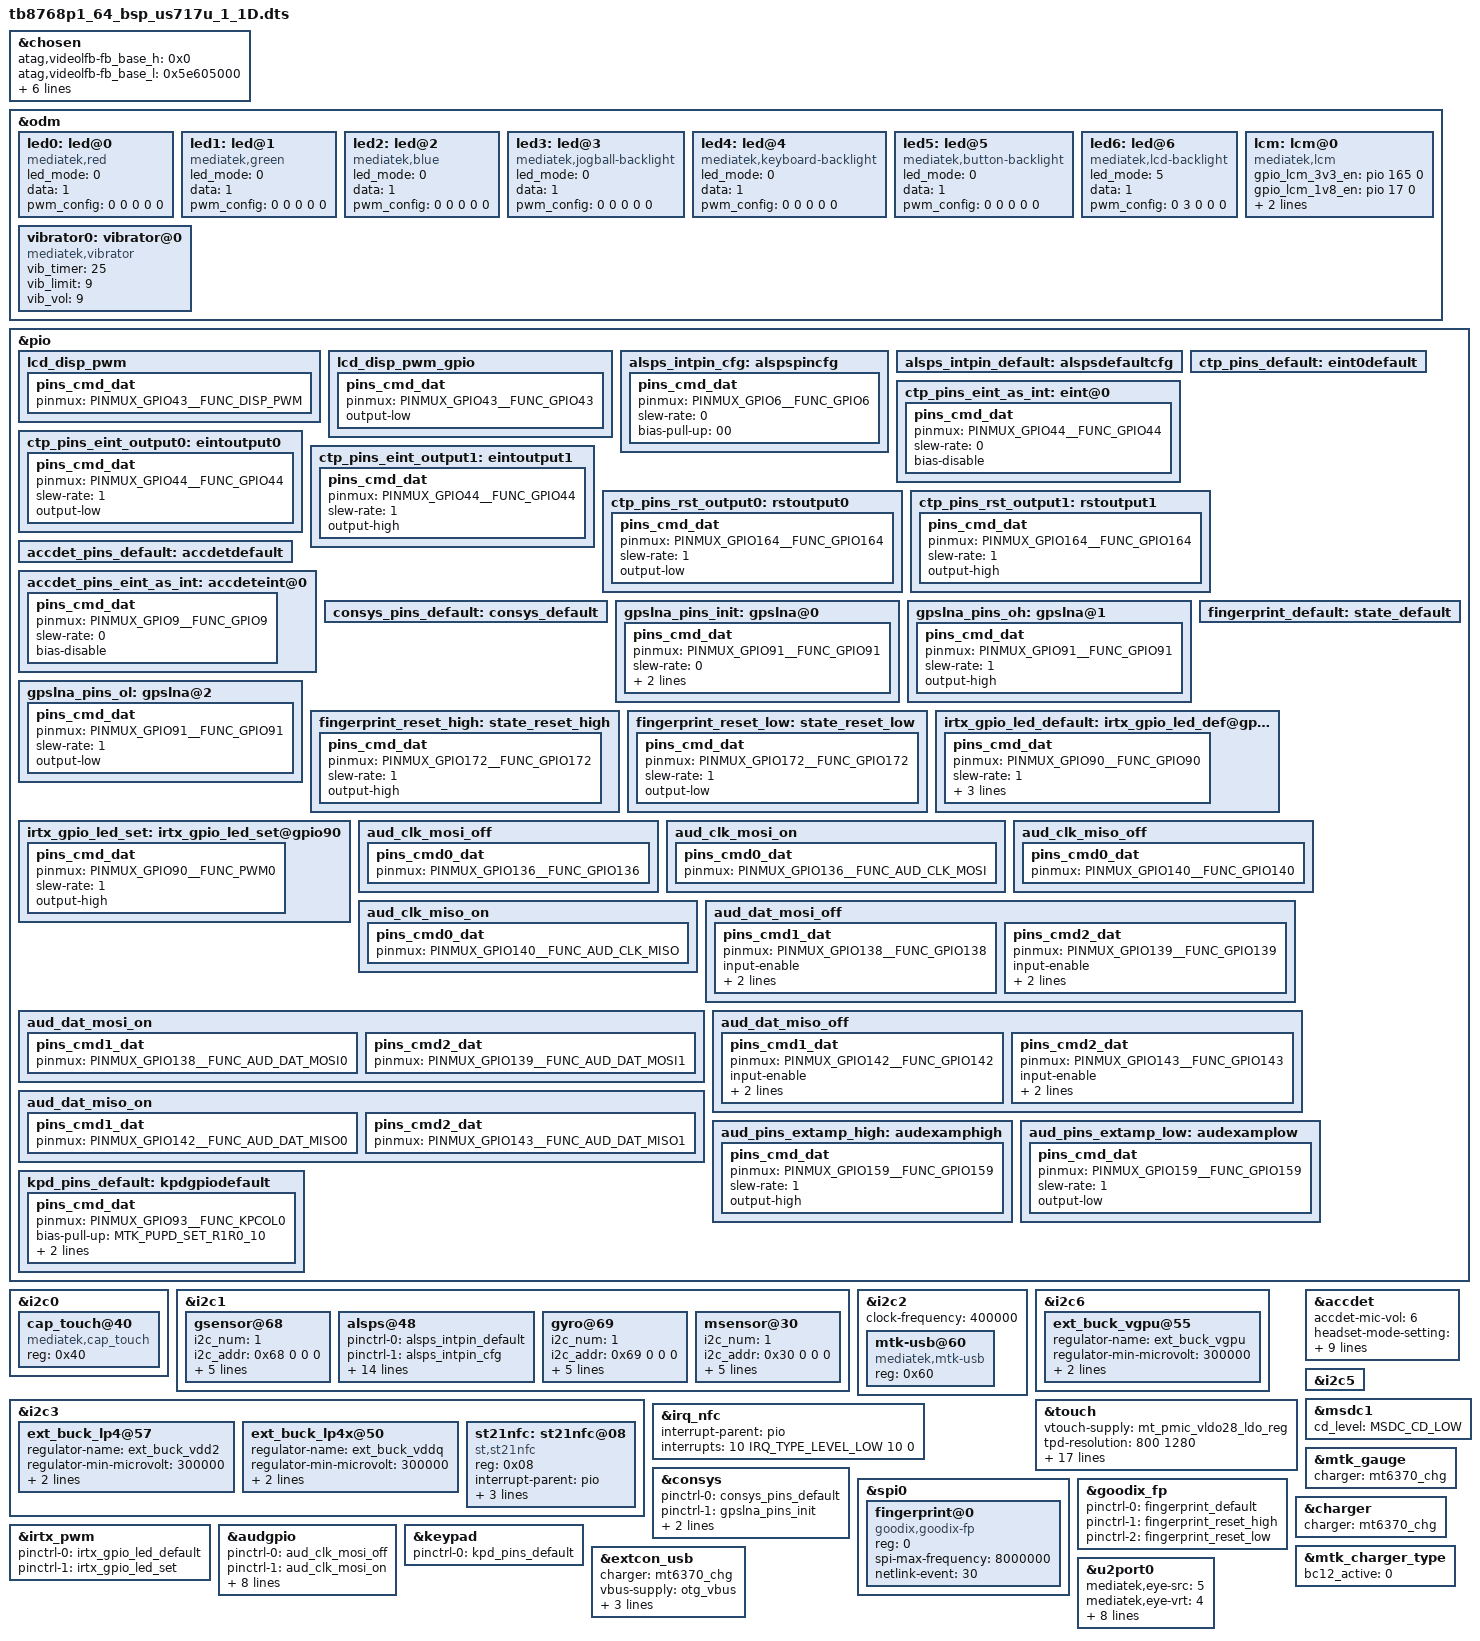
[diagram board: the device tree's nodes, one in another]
// SPDX-License-Identifier: GPL-2.0+
/*
 * Copyright (c) 2019 MediaTek Inc.
 *
 */

#include <dt-bindings/interrupt-controller/arm-gic.h>
#include <dt-bindings/interrupt-controller/irq.h>
#include <dt-bindings/pinctrl/mt6765-pinfunc.h>
#include <dt-bindings/clock/mt6765-clk.h>
#include <dt-bindings/mmc/mt6765-msdc.h>

/dts-v1/;
/plugin/;

/* chosen */
&chosen {

	/* fpga may has no lk, we need to specify display info here */
	/* fb buffer is reserved using this dts by memory node above */
	atag,videolfb-fb_base_h = <0x0>;
	atag,videolfb-fb_base_l = <0x5e605000>;
	atag,videolfb-islcmfound = <1>;
	/* because no lk, so lcm is not inited */
	atag,videolfb-islcm_inited = <0>;
	atag,videolfb-fps= <6000>;
	atag,videolfb-vramSize= <0x017bb000>;
	atag,videolfb-lcmname= "nt35695B_fhd_dsi_cmd_auo_rt5081_drv";
};

&odm {
	led0:led@0 {
		compatible = "mediatek,red";
		led_mode = <0>;
		data = <1>;
		pwm_config = <0 0 0 0 0>;
	};
	led1:led@1 {
		compatible = "mediatek,green";
		led_mode = <0>;
		data = <1>;
		pwm_config = <0 0 0 0 0>;
	};
	led2:led@2 {
		compatible = "mediatek,blue";
		led_mode = <0>;
		data = <1>;
		pwm_config = <0 0 0 0 0>;
	};
	led3:led@3 {
		compatible = "mediatek,jogball-backlight";
		led_mode = <0>;
		data = <1>;
		pwm_config = <0 0 0 0 0>;
	};
	led4:led@4 {
		compatible = "mediatek,keyboard-backlight";
		led_mode = <0>;
		data = <1>;
		pwm_config = <0 0 0 0 0>;
	};
	led5:led@5 {
		compatible = "mediatek,button-backlight";
		led_mode = <0>;
		data = <1>;
		pwm_config = <0 0 0 0 0>;
	};
	led6:led@6 {
		compatible = "mediatek,lcd-backlight";
		led_mode = <5>;
		data = <1>;
		pwm_config = <0 3 0 0 0>;
	};
	/*
	panel: panel@0 {
		compatible = "ft,ft8201";
		gpio_lcd_rst = <&pio 45 0>;
		gpio_lcd_led_en = <&pio 154 0>;
		gpio_lcd_pwr_enp = <&pio 167 0>;
		gpio_lcd_pwr_enn = <&pio 168 0>;
		pinctrl-names = "disp_pwm", "disp_pwm_gpio";
		pinctrl-0 = <&lcd_disp_pwm>;
		pinctrl-1 = <&lcd_disp_pwm_gpio>;
	};
	*/
	lcm: lcm@0{
		compatible = "mediatek,lcm";
		gpio_lcm_3v3_en = <&pio 165 0>; //3.3V
		gpio_lcm_1v8_en = <&pio 17 0>;
		gpio_lcm_rst = <&pio 45 0>;	 	//reset
		gpio_lcm_bias_en = <&pio 174 0>;//avdd avee
		status = "okay";
	};
	vibrator0:vibrator@0 {
		compatible = "mediatek,vibrator";
		vib_timer = <25>;
		vib_limit = <9>;
		vib_vol= <9>;
	};
};

&pio {
	lcd_disp_pwm: lcd_disp_pwm {
		pins_cmd_dat {
			pinmux = <PINMUX_GPIO43__FUNC_DISP_PWM>;
		};
	};

	lcd_disp_pwm_gpio: lcd_disp_pwm_gpio {
		pins_cmd_dat {
			pinmux = <PINMUX_GPIO43__FUNC_GPIO43>;
			output-low;
		};
	};
};

&i2c0 {
	cap_touch@40 {
		compatible = "mediatek,cap_touch" ;
		reg = < 0x40 > ;
		status = "okay" ;
	};
};
&i2c1 {
	gsensor@68{
		i2c_num = <1>;
		i2c_addr = <0x68 0 0 0>;
		direction = <7>;
		power_id = <0xffff>;
		power_vol = <0>;
		firlen = <16>;
		is_batch_supported = <0>;
	};
	
	alsps@48 {
		pinctrl-names = "pin_default", "pin_cfg";
		pinctrl-0 = <&alsps_intpin_default>;
		pinctrl-1 = <&alsps_intpin_cfg>;
		status = "okay";
		/* customization */
		i2c_num = <1>;
		i2c_addr = <0x48 0x0 0x0 0x00>;
		polling_mode_ps = <0>;
		polling_mode_als = <1>;
		power_id = <0xffff>;
		power_vol = <0>;
		als_level =
			<0 1 1 7 15 15 100 1000 2000 3000
			6000 10000 14000 18000 20000>;
		als_value =
			<40 40 90 90 160 160 225 320 640 1280
			1280 2600 2600 2600 10240 10240>;
		ps_threshold_high = <900>;
		ps_threshold_low = <600>;
		is_batch_supported_ps = <0>;
		is_batch_supported_als = <0>;
	};
	
	gyro@69 {
		i2c_num = <1>;
		i2c_addr = <0x69 0 0 0>;
		direction = <5>;
 		power_id = <0xffff>;
 		power_vol = <0>;
 		firlen = <16>;
 		is_batch_supported = <0>;
 	};

	msensor@30 {
		i2c_num = <1>;
		i2c_addr = <0x30 0 0 0>;
		direction = <6>;
		power_id = <0xffff>;
		power_vol = <0>;
		firlen = <16>;
		is_batch_supported = <0>;
	};
	
};
&i2c2 {
	#address-cells = <1>;
	#size-cells = <0>;
	clock-frequency = <400000>;

	mtk-usb@60 {
		compatible = "mediatek,mtk-usb";
		reg = <0x60>;
		status = "okay";
	};
};

&i2c3 {
	ext_buck_lp4@57 {
		regulator-name ="ext_buck_vdd2";
		regulator-min-microvolt = <300000>;
		regulator-max-microvolt = <1300000>;
		vsel_pin = <0>;
	};

	ext_buck_lp4x@50 {
		regulator-name ="ext_buck_vddq";
		regulator-min-microvolt = <300000>;
		regulator-max-microvolt = <1300000>;
		vsel_pin = <1>;
	};
	
    st21nfc: st21nfc@08 {
		compatible = "st,st21nfc";
		reg = <0x08>;
		interrupt-parent = <&pio>;
		interrupts = <10 IRQ_TYPE_EDGE_FALLING 10 0>;//U23
		reset-gpios = <&pio 9 0x0>;//V24
		irq-gpios = <&pio 10 0x0>;
		status = "okay";
	};

};

&i2c6 {
	ext_buck_vgpu@55 {
		regulator-name ="ext_buck_vgpu";
		regulator-min-microvolt = <300000>;
		regulator-max-microvolt = <1300000>;
		vsel_pin = <2>;
	};
};
&pio {
	alsps_intpin_cfg: alspspincfg {
	    pins_cmd_dat {
			pinmux = <PINMUX_GPIO6__FUNC_GPIO6>;
			slew-rate = <0>;
			bias-pull-up = <00>;
		};
	};

	alsps_intpin_default: alspsdefaultcfg {

	};
};
/* TOUCH start */
&touch {
	vtouch-supply = <&mt_pmic_vldo28_ldo_reg>;
	tpd-resolution = <800 1280>;
	use-tpd-button = <0>;
	tpd-key-num = <3>;
	tpd-key-local= <139 172 158 0>;
	tpd-key-dim-local = <90 883 100 40 230
				 883 100 40 370 883 100 40 0 0 0 0>;
	tpd-max-touch-num = <10>;
	tpd-filter-enable = <0>;
	tpd-filter-pixel-density = <106>;
	tpd-filter-custom-prameters = <0 0 0 0 0 0 0 0 0 0 0 0>;
	tpd-filter-custom-speed = <0 0 0>;
	pinctrl-names = "default", "state_eint_as_int", "state_eint_output0",
		"state_eint_output1", "state_rst_output0", "state_rst_output1";
	pinctrl-0 = <&ctp_pins_default>;
	pinctrl-1 = <&ctp_pins_eint_as_int>;
	pinctrl-2 = <&ctp_pins_eint_output0>;
	pinctrl-3 = <&ctp_pins_eint_output1>;
	pinctrl-4 = <&ctp_pins_rst_output0>;
	pinctrl-5 = <&ctp_pins_rst_output1>;
	status = "okay";
};


&irq_nfc {
	   interrupt-parent = <&pio>;
	   interrupts = <10 IRQ_TYPE_LEVEL_LOW 10 0>;
};

&pio {
	ctp_pins_default: eint0default {
	};
	ctp_pins_eint_as_int: eint@0 {
		pins_cmd_dat {
			/*pinmux = <PINMUX_GPIO0__FUNC_GPIO0>;*/    //pin for US717 1.0D 
			pinmux = <PINMUX_GPIO44__FUNC_GPIO44>;		//pin for US717 1.1D 
			slew-rate = <0>;
			bias-disable;
		};
	};
	ctp_pins_eint_output0: eintoutput0 {
		pins_cmd_dat {
			/*pinmux = <PINMUX_GPIO0__FUNC_GPIO0>;*/  		 //pin for US717 1.0D 
			pinmux = <PINMUX_GPIO44__FUNC_GPIO44>;   	 		 //pin for US717 1.1D 
			slew-rate = <1>;
			output-low;
		};
	};
	ctp_pins_eint_output1: eintoutput1 {
		pins_cmd_dat {
			/*pinmux = <PINMUX_GPIO0__FUNC_GPIO0>;*/   		//pin for US717 1.0D 
			pinmux = <PINMUX_GPIO44__FUNC_GPIO44>; 				//pin for US717 1.1D 
			slew-rate = <1>;
			output-high;
		};
	};
	ctp_pins_rst_output0: rstoutput0 {
		pins_cmd_dat {
			pinmux = <PINMUX_GPIO164__FUNC_GPIO164>;
			slew-rate = <1>;
			output-low;
		};
	};
	ctp_pins_rst_output1: rstoutput1 {
		pins_cmd_dat {
			pinmux = <PINMUX_GPIO164__FUNC_GPIO164>;
			slew-rate = <1>;
			output-high;
		};
	};
};
/* TOUCH end */

&accdet {
	accdet-mic-vol = <6>;
	headset-mode-setting = <0x500 0x500 1 0x1f0 0x800 0x800 0x20 0x44>;
	accdet-plugout-debounce = <1>;
	accdet-mic-mode = <1>;
	headset-eint-level-pol = <8>;
	headset-three-key-threshold = <0 80 220 400>;
	headset-three-key-threshold-CDD = <0 121 192 600>;
	headset-four-key-threshold = <0 58 121 192 400>;
	pinctrl-names = "default", "state_eint_as_int";
	pinctrl-0 = <&accdet_pins_default>;
	pinctrl-1 = <&accdet_pins_eint_as_int>;
	status = "okay";
};
&pio {
	accdet_pins_default: accdetdefault {
	};
	accdet_pins_eint_as_int: accdeteint@0 {
		pins_cmd_dat {
			pinmux = <PINMUX_GPIO9__FUNC_GPIO9>;
			slew-rate = <0>;
			bias-disable;
		};
	};
};

&i2c5 {


};

/* CONSYS GPIO standardization */
&pio {
	consys_pins_default: consys_default {
	};
	gpslna_pins_init: gpslna@0 {
		pins_cmd_dat {
			pinmux = <PINMUX_GPIO91__FUNC_GPIO91>;
			slew-rate = <0>;
			bias-disable;
			output-low;
		};
	};
	gpslna_pins_oh: gpslna@1 {
		pins_cmd_dat {
			pinmux = <PINMUX_GPIO91__FUNC_GPIO91>;
			slew-rate = <1>;
			output-high;
		};
	};
	gpslna_pins_ol: gpslna@2 {
		pins_cmd_dat {
			pinmux = <PINMUX_GPIO91__FUNC_GPIO91>;
			slew-rate = <1>;
			output-low;
		};
	};
};
&consys {
	pinctrl-names = "default", "gps_lna_state_init",
		"gps_lna_state_oh", "gps_lna_state_ol";
	pinctrl-0 = <&consys_pins_default>;
	pinctrl-1 = <&gpslna_pins_init>;
	pinctrl-2 = <&gpslna_pins_oh>;
	pinctrl-3 = <&gpslna_pins_ol>;
	status = "okay";
};
/* CONSYS end */
/* FINGERPRINT start */
&spi0 {
	#address-cells = <1>;
	#size-cells = <0>;
	fingerprint@0 {
		compatible = "goodix,goodix-fp";
		reg = <0>;
		spi-max-frequency = <8000000>;
		netlink-event = <30>;
		status = "okay";
	};
};

&goodix_fp {
	pinctrl-names = "default", "reset_high", "reset_low";
	pinctrl-0 = <&fingerprint_default>;
	pinctrl-1 = <&fingerprint_reset_high>;
	pinctrl-2 = <&fingerprint_reset_low>;
	status = "okay";
};

&pio {
	fingerprint_default: state_default {
	};
	fingerprint_reset_high: state_reset_high {
		pins_cmd_dat {
			pinmux = <PINMUX_GPIO172__FUNC_GPIO172>;
			slew-rate = <1>;
			output-high;
		};
	};
	fingerprint_reset_low: state_reset_low {
		pins_cmd_dat {
			pinmux = <PINMUX_GPIO172__FUNC_GPIO172>;
			slew-rate = <1>;
			output-low;
		};
	};
};
/* FINGERPRINT end */

/* IRTX GPIO end */
&irtx_pwm {
	pinctrl-names = "irtx_gpio_led_default", "irtx_gpio_led_set";
	pinctrl-0 = <&irtx_gpio_led_default>;
	pinctrl-1 = <&irtx_gpio_led_set>;
	status = "okay";
};
&pio {
	irtx_gpio_led_default:irtx_gpio_led_def@gpio90 {
		pins_cmd_dat {
			pinmux = <PINMUX_GPIO90__FUNC_GPIO90>;
			slew-rate = <1>;
			bias-disable;
			output-low;
			input-schmitt-enable = <0>;
		};
	};

	irtx_gpio_led_set:irtx_gpio_led_set@gpio90 {
		pins_cmd_dat {
			pinmux = <PINMUX_GPIO90__FUNC_PWM0>;
			slew-rate = <1>;
			output-high;
		};
	};
};
/* IRTX GPIO Settings -End */

/* AUDIO GPIO standardization */
&audgpio {
	pinctrl-names = "aud_clk_mosi_off",
			"aud_clk_mosi_on",
			"aud_clk_miso_off",
			"aud_clk_miso_on",
			"aud_dat_mosi_off",
			"aud_dat_mosi_on",
			"aud_dat_miso_off",
			"aud_dat_miso_on",
			"extamp-pullhigh",
			"extamp-pulllow";

	pinctrl-0 = <&aud_clk_mosi_off>;
	pinctrl-1 = <&aud_clk_mosi_on>;
	pinctrl-2 = <&aud_clk_miso_off>;
	pinctrl-3 = <&aud_clk_miso_on>;
	pinctrl-4 = <&aud_dat_mosi_off>;
	pinctrl-5 = <&aud_dat_mosi_on>;
	pinctrl-6 = <&aud_dat_miso_off>;
	pinctrl-7 = <&aud_dat_miso_on>;
	pinctrl-8 = <&aud_pins_extamp_high>;
	pinctrl-9 = <&aud_pins_extamp_low>;
	status = "okay";
};

&pio {
	aud_clk_mosi_off: aud_clk_mosi_off {
		pins_cmd0_dat {
			pinmux = <PINMUX_GPIO136__FUNC_GPIO136>;
		};
	};

	aud_clk_mosi_on: aud_clk_mosi_on {
		pins_cmd0_dat {
			pinmux = <PINMUX_GPIO136__FUNC_AUD_CLK_MOSI>;
		};
	};

	aud_clk_miso_off: aud_clk_miso_off {
		pins_cmd0_dat {
			pinmux = <PINMUX_GPIO140__FUNC_GPIO140>;
		};
	};

	aud_clk_miso_on: aud_clk_miso_on {
		pins_cmd0_dat {
			pinmux = <PINMUX_GPIO140__FUNC_AUD_CLK_MISO>;
		};
	};

	aud_dat_mosi_off: aud_dat_mosi_off {
		pins_cmd1_dat {
			pinmux = <PINMUX_GPIO138__FUNC_GPIO138>;
			input-enable;
			slew-rate = <0>;
			bias-disable;
		};
		pins_cmd2_dat {
			pinmux = <PINMUX_GPIO139__FUNC_GPIO139>;
			input-enable;
			slew-rate = <0>;
			bias-disable;
		};
	};

	aud_dat_mosi_on: aud_dat_mosi_on {
		pins_cmd1_dat {
			pinmux = <PINMUX_GPIO138__FUNC_AUD_DAT_MOSI0>;
		};
		pins_cmd2_dat {
			pinmux = <PINMUX_GPIO139__FUNC_AUD_DAT_MOSI1>;
		};
	};

	aud_dat_miso_off: aud_dat_miso_off {
		pins_cmd1_dat {
			pinmux = <PINMUX_GPIO142__FUNC_GPIO142>;
			input-enable;
			slew-rate = <0>;
			bias-disable;
		};
		pins_cmd2_dat {
			pinmux = <PINMUX_GPIO143__FUNC_GPIO143>;
			input-enable;
			slew-rate = <0>;
			bias-disable;
		};
	};

	aud_dat_miso_on: aud_dat_miso_on {
		pins_cmd1_dat {
			pinmux = <PINMUX_GPIO142__FUNC_AUD_DAT_MISO0>;
		};
		pins_cmd2_dat {
			pinmux = <PINMUX_GPIO143__FUNC_AUD_DAT_MISO1>;
		};
	};

	aud_pins_extamp_high: audexamphigh {
		pins_cmd_dat {
			pinmux = <PINMUX_GPIO159__FUNC_GPIO159>;
			slew-rate = <1>;
			output-high;
		};
	};

	aud_pins_extamp_low: audexamplow {
		pins_cmd_dat {
			pinmux = <PINMUX_GPIO159__FUNC_GPIO159>;
			slew-rate = <1>;
			output-low;
		};
	};
};
/* AUDIO end */

&msdc1 {
	cd_level = /bits/ 8 <MSDC_CD_LOW>;
};

&keypad {
	pinctrl-names = "default";
	pinctrl-0 = <&kpd_pins_default>;
};

&pio {
	kpd_pins_default: kpdgpiodefault {
		pins_cmd_dat {
			pinmux = <PINMUX_GPIO93__FUNC_KPCOL0>;
			bias-pull-up = <MTK_PUPD_SET_R1R0_10>;
			output-low;
			input-schmitt-enable;
		};
	};
};

/* FLASHLIGHT GPIO standardization */

/*
&odm {
	flashlights_led191: flashlights_led191 {
		compatible = "mediatek,flashlights_led191";
	};
};

&flashlights_led191 {
	pinctrl-names = "flashlight_default",
			"hwen_high",
			"hwen_low",
			"hw_ch1_high",
			"hw_ch1_low";

	pinctrl-0 = <&flashlight_pins_default>;
	pinctrl-1 = <&flashlight_pins_hw_ch0_high>;
	pinctrl-2 = <&flashlight_pins_hw_ch0_low>;
	pinctrl-3 = <&flashlight_pins_hw_ch1_high>;
	pinctrl-4 = <&flashlight_pins_hw_ch1_low>;

	status = "okay";
};

&pio {
	flashlight_pins_default: flashlight_pins_default {
	};

	flashlight_pins_hw_ch0_high: flashlight_pins_hw_ch0_high {
		pins_cmd_dat {
			//pinmux = <PINMUX_GPIO10__FUNC_GPIO10>;
			slew-rate = <1>;
			output-high;
		};
	};

	flashlight_pins_hw_ch0_low: flashlight_pins_hw_ch0_low {
		pins_cmd_dat {
			//pinmux = <PINMUX_GPIO10__FUNC_GPIO10>;
			slew-rate = <1>;
			output-low;
		};
	};

	flashlight_pins_hw_ch1_high: flashlight_pins_hw_ch1_high {
		pins_cmd_dat {
			pinmux = <PINMUX_GPIO14__FUNC_GPIO14>;
			slew-rate = <1>;
			output-high;
		};
	};

	flashlight_pins_hw_ch1_low: flashlight_pins_hw_ch1_low {
		pins_cmd_dat {
			pinmux = <PINMUX_GPIO14__FUNC_GPIO14>;
			slew-rate = <1>;
			output-low;
		};
	};
};
*/

/* FLASHLIGHT end */

&mtk_gauge {
	charger = <&mt6370_chg>;
};

&charger {
	charger = <&mt6370_chg>;
};

&mtk_charger_type {
	bc12_active = <0>;
};

&extcon_usb {
	charger = <&mt6370_chg>;
	vbus-supply = <&otg_vbus>;
	vbus-current;
	vbus-voltage;
	id-gpios = <&pio 41 0x0>;
};

&u2port0 {
	mediatek,eye-src = <5>;
	mediatek,eye-vrt = <4>;
	mediatek,eye-term = <4>;
	mediatek,eye-rev6 = <1>;
	mediatek,eye-disc = <15>;
	mediatek,host-eye-src = <5>;
	mediatek,host-eye-vrt = <4>;
	mediatek,host-eye-term = <4>;
	mediatek,host-eye-rev6 = <1>;
	mediatek,host-eye-disc = <15>;
};

#include <tb8768p1_64_bsp/cust.dtsi>
#include "mediatek/cust_mt8768_camera.dtsi"

/*End of this file, DO NOT ADD ANYTHING HERE*/
